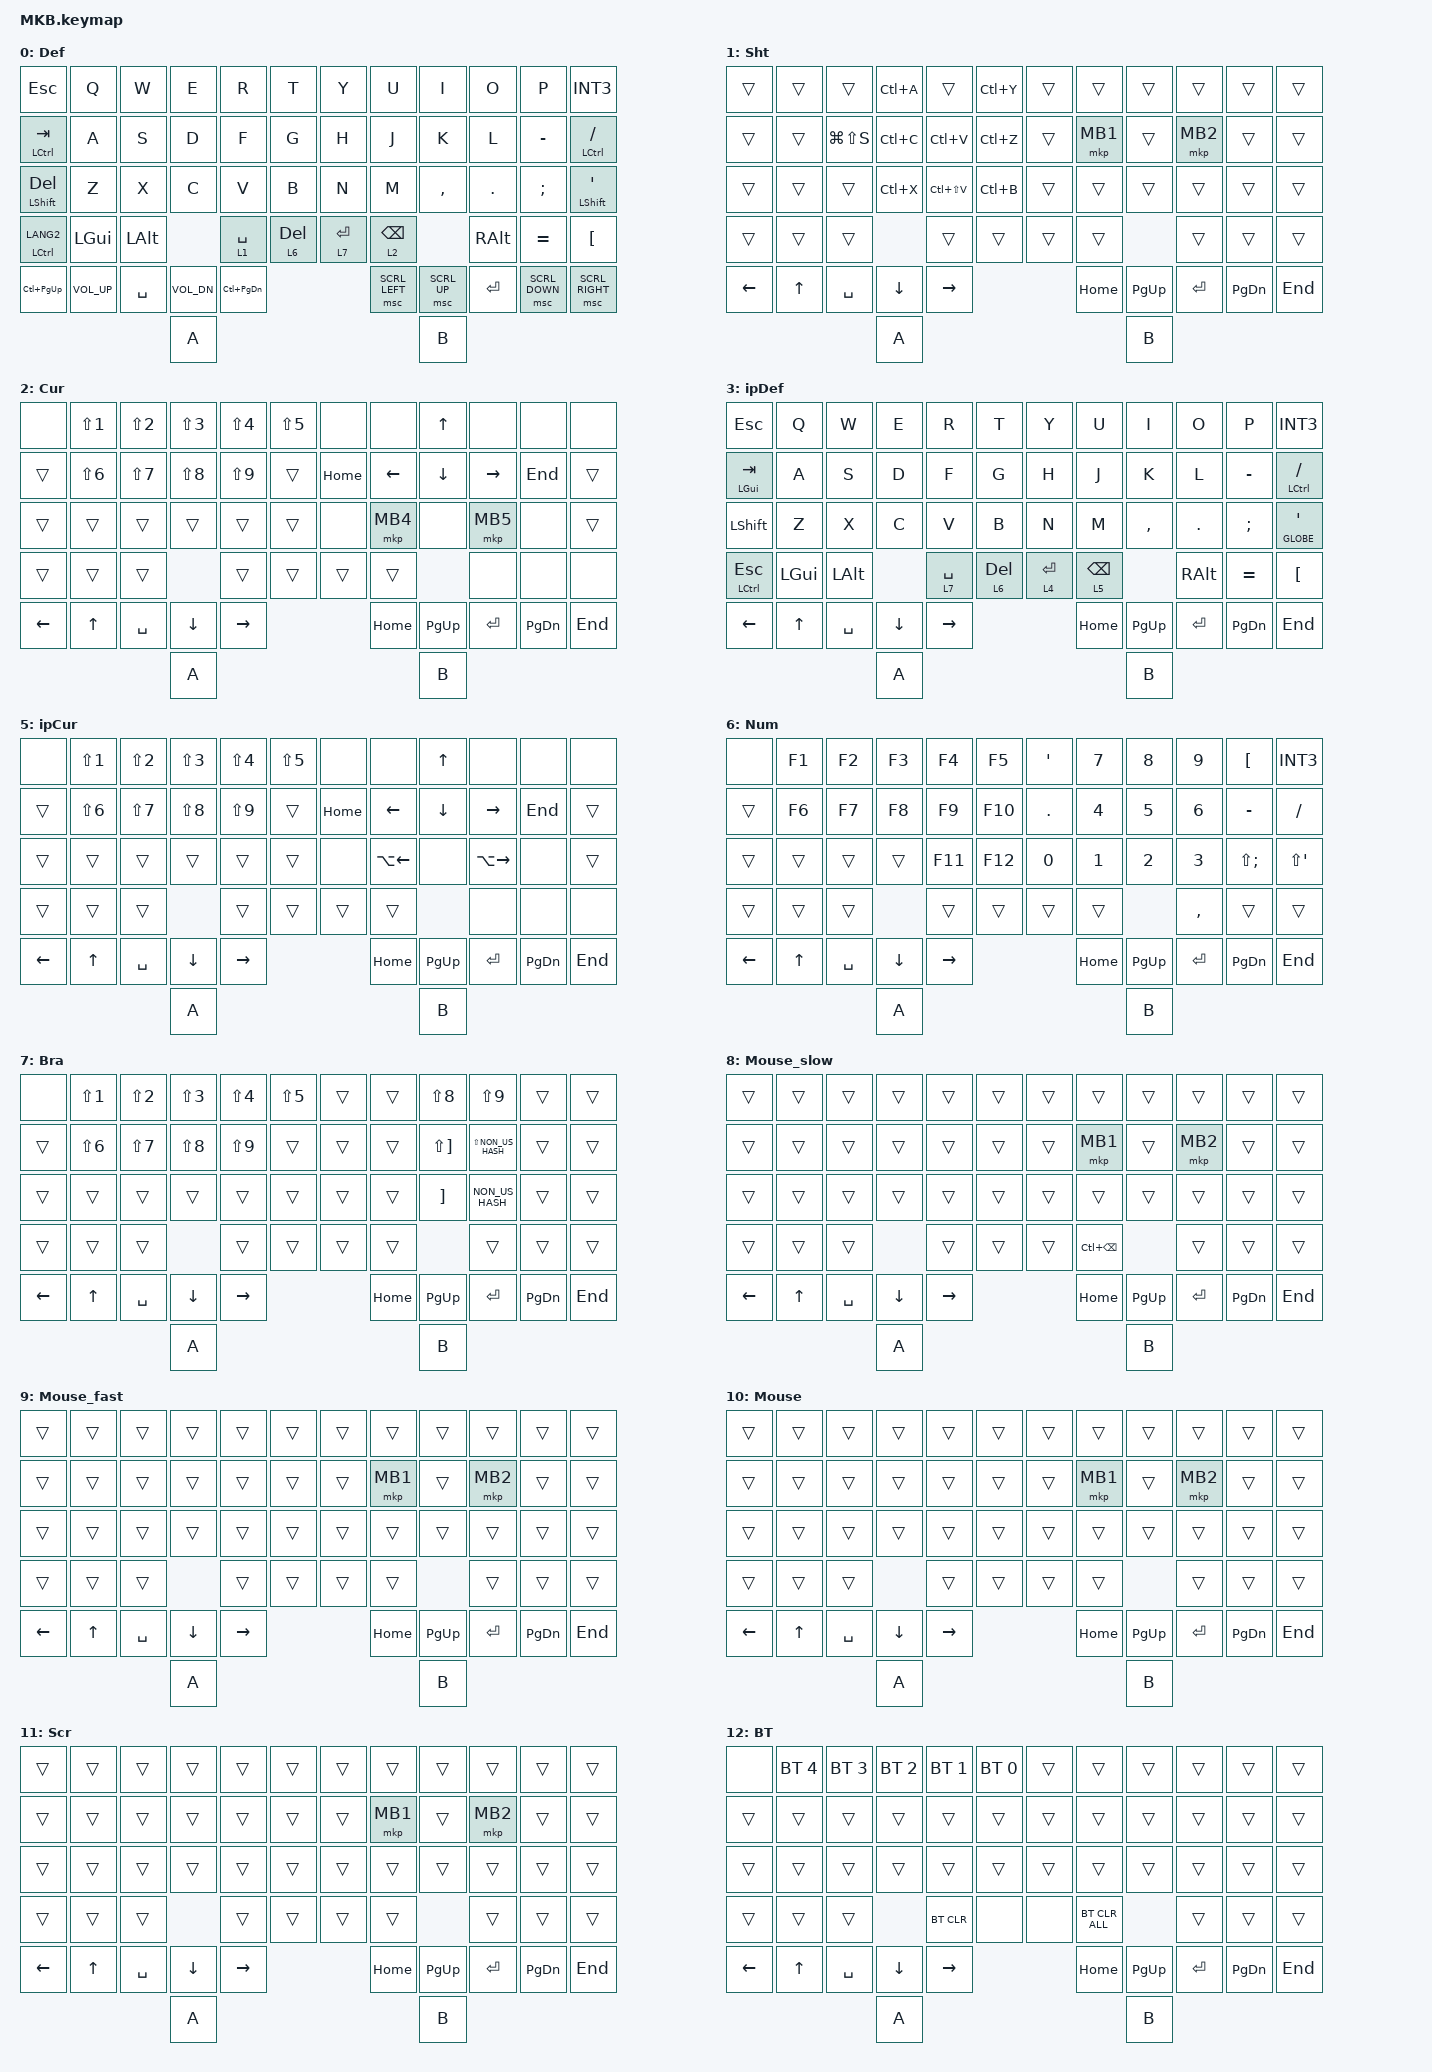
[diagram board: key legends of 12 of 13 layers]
// #include <layout_shift.dtsi>

#include <layout_shift_kp_override.dtsi>
#include <behaviors.dtsi>
#include <dt-bindings/zmk/bt.h>
#include <dt-bindings/zmk/keys.h>
#include <dt-bindings/zmk/pointing.h>

#define DEF 0
#define FUNC 1
#define NUM 2
#define MOUSE 3
#define SCROLL 4
#define BT 5

&mt {
    flavor = "balanced";
    tapping-term-ms = <280>;
    quick-tap-ms = <175>;
    require-prior-idle-ms = <150>;
};

/ {
    combos {
        compatible = "zmk,combos";

        scroll_lang1 {
            bindings = <&lt 11 LANG1>;
            key-positions = <19 20>;
        };

        lang2 {
            bindings = <&kp LANGUAGE_2>;
            key-positions = <15 16>;
        };

        underscore {
            bindings = <&kp LS(INT1)>;
            key-positions = <21 22>;
            layers = <0 6 7 3>;
        };

        shift1 {
            bindings = <&kp LS(N1)>;
            key-positions = <27 28>;
            layers = <0 6 7 3>;
        };

        question {
            bindings = <&kp LS(SLASH)>;
            key-positions = <31 32>;
            layers = <0 6 7 3>;
        };

        bt {
            bindings = <&mo 12>;
            key-positions = <18 23>;
            layers = <0 3>;
        };

        macro_bra_s {
            bindings = <&macro_bra_s>;
            key-positions = <8 9>;
            layers = <0 6 7 3>;
        };

        macro_bra_m {
            bindings = <&macro_bro_m>;
            key-positions = <20 21>;
            layers = <6 7 0 3>;
        };

        macro_bra_l {
            bindings = <&macro_bro_l>;
            key-positions = <32 33>;
            layers = <0 6 7 3>;
        };

        macro_dq {
            bindings = <&macro_dq>;
            key-positions = <2 3>;
            layers = <0 6 7 3>;
        };

        macro_sq {
            bindings = <&macro_sq>;
            key-positions = <14 15>;
            layers = <0 6 7 3>;
        };

        macro_bra_ket {
            bindings = <&macro_bra_ket>;
            key-positions = <26 27>;
            layers = <0 6 7 3>;
        };

        switch_ipad {
            bindings = <&tog 3>;
            key-positions = <12 17>;
            layers = <0 3>;
        };

        delete {
            bindings = <&kp DEL>;
            key-positions = <10 11>;
        };

        mouse3 {
            bindings = <&mkp MB3>;
            key-positions = <19 21>;
        };
    };

    macros {
        macro_bra_s: new_macro {
            compatible = "zmk,behavior-macro";
            #binding-cells = <0>;
            bindings = <&kp LS(N8) &kp LS(N9) &kp LEFT>;
            label = "NEW_MACRO";
        };

        macro_bro_m: macro_bro_m {
            compatible = "zmk,behavior-macro";
            #binding-cells = <0>;
            bindings = <&kp LS(RIGHT_BRACKET) &kp LS(NON_US_HASH) &kp LEFT>;
            label = "MACRO_BRO_M";
        };

        macro_bro_l: macro_bro_L {
            compatible = "zmk,behavior-macro";
            #binding-cells = <0>;
            bindings = <&kp RIGHT_BRACKET &kp NON_US_HASH &kp LEFT>;
            label = "MACRO_BRO_L";
        };

        macro_dq: macro_dq {
            compatible = "zmk,behavior-macro";
            #binding-cells = <0>;
            bindings = <&kp LS(N2) &kp LS(N2) &kp LEFT>;
            label = "MACRO_DQ";
        };

        macro_sq: macro_sq {
            compatible = "zmk,behavior-macro";
            #binding-cells = <0>;
            bindings = <&kp LS(N7) &kp LS(N7) &kp LEFT>;
            label = "MACRO_SQ";
        };

        macro_bra_ket: macro_bra_ket {
            compatible = "zmk,behavior-macro";
            #binding-cells = <0>;
            bindings = <&kp LS(COMMA) &kp LS(DOT) &kp LEFT>;
            label = "MACRO_BRA_KET";
        };
    };

    keymap {
        compatible = "zmk,keymap";

        default_layer {
            label = "Def";
            bindings = <
&kp ESCAPE        &kp Q         &kp W      &kp E         &kp R              &kp T             &kp Y        &kp U            &kp I         &kp O          &kp P           &kp INT3
&mt LCTRL TAB     &kp A         &kp S      &kp D         &kp F              &kp G             &kp H        &kp J            &kp K         &kp L          &kp MINUS       &mt LCTRL SLASH
&mt LSHFT DELETE  &kp Z         &kp X      &kp C         &kp V              &kp B             &kp N        &kp M            &kp COMMA     &kp DOT        &kp SEMICOLON   &mt LSHIFT SINGLE_QUOTE
&mt LCTRL LANG2   &kp LGUI      &kp LALT                 &lt 1 SPACE        &lt 6 DELETE      &lt 7 ENTER  &lt 2 BACKSPACE                &kp RIGHT_ALT  &kp EQUAL       &kp LEFT_BRACKET
&kp LC(PAGE_UP)   &kp C_VOL_UP  &kp SPACE  &kp C_VOL_DN  &kp LC(PAGE_DOWN)                                 &msc SCRL_LEFT   &msc SCRL_UP  &kp ENTER      &msc SCRL_DOWN  &msc SCRL_RIGHT
                                           &kp A                                                                            &kp B
            >;

            sensor-bindings = <&inc_dec_kp C_VOL_UP C_VOL_DN &inc_dec_kp PG_UP PG_DN>;
        };

        shortcut_layer {
            label = "Sht";
            bindings = <
&trans    &trans  &trans         &kp LC(A)  &trans         &kp LC(Y)      &trans  &trans    &trans     &trans     &trans     &trans
&trans    &trans  &kp LG(LS(S))  &kp LC(C)  &kp LC(V)      &kp LC(Z)      &trans  &mkp MB1  &trans     &mkp MB2   &trans     &trans
&trans    &trans  &trans         &kp LC(X)  &kp LC(LS(V))  &kp LC(B)      &trans  &trans    &trans     &trans     &trans     &trans
&trans    &trans  &trans                    &trans         &trans         &trans  &trans               &trans     &trans     &trans
&kp LEFT  &kp UP  &kp SPACE      &kp DOWN   &kp RIGHT                             &kp HOME  &kp PG_UP  &kp ENTER  &kp PG_DN  &kp END
                                 &kp A                                                      &kp B
            >;

            sensor-bindings = <&inc_dec_kp C_VOL_UP C_VOL_DN &inc_dec_kp PG_UP PG_DN>;
        };

        cursor_layer {
            label = "Cur";
            bindings = <
&none     &kp LS(N1)        &kp LS(N2)  &kp LS(N3)  &kp LS(N4)  &kp LS(NUMBER_5)      &none     &none     &kp UP     &none      &none      &none
&trans    &kp LS(NUMBER_6)  &kp LS(N7)  &kp LS(N8)  &kp LS(N9)  &trans                &kp HOME  &kp LEFT  &kp DOWN   &kp RIGHT  &kp END    &trans
&trans    &trans            &trans      &trans      &trans      &trans                &none     &mkp MB4  &none      &mkp MB5   &none      &trans
&trans    &trans            &trans                  &trans      &trans                &trans    &trans               &none      &none      &none
&kp LEFT  &kp UP            &kp SPACE   &kp DOWN    &kp RIGHT                                   &kp HOME  &kp PG_UP  &kp ENTER  &kp PG_DN  &kp END
                                        &kp A                                                             &kp B
            >;

            sensor-bindings =
                <&inc_dec_kp C_VOL_UP C_VOL_DN>,
                <&inc_dec_kp PG_UP PG_DN>;
        };

        ipad_default_layer {
            label = "ipDef";
            bindings = <
&kp ESC           &kp Q         &kp W      &kp E     &kp R        &kp T          &kp Y        &kp U            &kp I      &kp O          &kp P          &kp INT3
&mt LEFT_GUI TAB  &kp A         &kp S      &kp D     &kp F        &kp G          &kp H        &kp J            &kp K      &kp L          &kp MINUS      &mt LCTRL SLASH
&kp LSHFT         &kp Z         &kp X      &kp C     &kp V        &kp B          &kp N        &kp M            &kp COMMA  &kp DOT        &kp SEMICOLON  &mt GLOBE SINGLE_QUOTE
&mt LCTRL ESC     &kp LEFT_GUI  &kp LALT             &lt 7 SPACE  &lt 6 DEL      &lt 4 ENTER  &lt 5 BACKSPACE             &kp RIGHT_ALT  &kp EQUAL      &kp LEFT_BRACKET
&kp LEFT          &kp UP        &kp SPACE  &kp DOWN  &kp RIGHT                                &kp HOME         &kp PG_UP  &kp ENTER      &kp PG_DN      &kp END
                                           &kp A                                                               &kp B
            >;

            sensor-bindings =
                <&inc_dec_kp C_VOL_UP C_VOL_DN>,
                <&inc_dec_kp PG_UP PG_DN>;
        };

        ipad_function_layer {
            label = "ipFnc";
            bindings = <
&trans    &trans  &trans     &trans    &trans     &trans             &trans         &kp LG(A)  &trans             &trans          &trans     &trans
&trans    &trans  &trans     &trans    &trans     &trans             &kp LG(Z)      &kp LG(C)  &kp LG(V)          &kp LS(LG(N3))  &trans     &trans
&trans    &trans  &trans     &trans    &trans     &trans             &kp LG(LS(Z))  &kp LG(X)  &kp LS(LA(LG(V)))  &trans          &trans     &trans
&trans    &trans  &trans               &kp LG(Z)  &kp LS(LG(Z))      &trans         &trans                        &trans          &trans     &trans
&kp LEFT  &kp UP  &kp SPACE  &kp DOWN  &kp RIGHT                                    &kp HOME   &kp PG_UP          &kp ENTER       &kp PG_DN  &kp END
                             &kp A                                                             &kp B
            >;

            sensor-bindings =
                <&inc_dec_kp C_VOL_UP C_VOL_DN>,
                <&inc_dec_kp PG_UP PG_DN>;
        };

        ipad_cursor_layer {
            label = "ipCur";
            bindings = <
&none     &kp LS(N1)        &kp LS(N2)  &kp LS(N3)  &kp LS(N4)  &kp LS(NUMBER_5)      &none     &none         &kp UP     &none          &none      &none
&trans    &kp LS(NUMBER_6)  &kp LS(N7)  &kp LS(N8)  &kp LS(N9)  &trans                &kp HOME  &kp LEFT      &kp DOWN   &kp RIGHT      &kp END    &trans
&trans    &trans            &trans      &trans      &trans      &trans                &none     &kp LA(LEFT)  &none      &kp LA(RIGHT)  &none      &trans
&trans    &trans            &trans                  &trans      &trans                &trans    &trans                   &none          &none      &none
&kp LEFT  &kp UP            &kp SPACE   &kp DOWN    &kp RIGHT                                   &kp HOME      &kp PG_UP  &kp ENTER      &kp PG_DN  &kp END
                                        &kp A                                                                 &kp B
            >;

            sensor-bindings =
                <&inc_dec_kp C_VOL_UP C_VOL_DN>,
                <&inc_dec_kp PG_UP PG_DN>;
        };

        num_layer {
            label = "Num";
            bindings = <
&none     &kp F1  &kp F2     &kp F3    &kp F4     &kp F5       &kp SINGLE_QUOTE  &kp N7    &kp N8     &kp N9     &kp LEFT_BRACKET   &kp INT3
&trans    &kp F6  &kp F7     &kp F8    &kp F9     &kp F10      &kp PERIOD        &kp N4    &kp N5     &kp N6     &kp MINUS          &kp SLASH
&trans    &trans  &trans     &trans    &kp F11    &kp F12      &kp N0            &kp N1    &kp N2     &kp N3     &kp LS(SEMICOLON)  &kp LS(SINGLE_QUOTE)
&trans    &trans  &trans               &trans     &trans       &trans            &trans               &kp COMMA  &trans             &trans
&kp LEFT  &kp UP  &kp SPACE  &kp DOWN  &kp RIGHT                                 &kp HOME  &kp PG_UP  &kp ENTER  &kp PG_DN          &kp END
                             &kp A                                                         &kp B
            >;

            sensor-bindings = <&inc_dec_kp C_VOL_UP C_VOL_DN &inc_dec_kp PG_UP PG_DN>;
        };

        bracket_layer {
            label = "Bra";
            bindings = <
&none     &kp LS(N1)  &kp LS(N2)  &kp LS(N3)  &kp LS(N4)  &kp LS(N5)      &trans  &trans    &kp LS(N8)             &kp LS(N9)           &trans     &trans
&trans    &kp LS(N6)  &kp LS(N7)  &kp LS(N8)  &kp LS(N9)  &trans          &trans  &trans    &kp LS(RIGHT_BRACKET)  &kp LS(NON_US_HASH)  &trans     &trans
&trans    &trans      &trans      &trans      &trans      &trans          &trans  &trans    &kp RIGHT_BRACKET      &kp NON_US_HASH      &trans     &trans
&trans    &trans      &trans                  &trans      &trans          &trans  &trans                           &trans               &trans     &trans
&kp LEFT  &kp UP      &kp SPACE   &kp DOWN    &kp RIGHT                           &kp HOME  &kp PG_UP              &kp ENTER            &kp PG_DN  &kp END
                                  &kp A                                                     &kp B
            >;

            sensor-bindings =
                <&inc_dec_kp C_VOL_UP C_VOL_DN>,
                <&inc_dec_kp PG_UP PG_DN>;
        };

        mouse_slow_layer {
            label = "Mouse_slow";
            bindings = <
&trans    &trans  &trans     &trans    &trans     &trans      &trans  &trans             &trans     &trans     &trans     &trans
&trans    &trans  &trans     &trans    &trans     &trans      &trans  &mkp MB1           &trans     &mkp MB2   &trans     &trans
&trans    &trans  &trans     &trans    &trans     &trans      &trans  &trans             &trans     &trans     &trans     &trans
&trans    &trans  &trans               &trans     &trans      &trans  &kp LC(BACKSPACE)             &trans     &trans     &trans
&kp LEFT  &kp UP  &kp SPACE  &kp DOWN  &kp RIGHT                      &kp HOME           &kp PG_UP  &kp ENTER  &kp PG_DN  &kp END
                             &kp A                                                       &kp B
            >;

            sensor-bindings =
                <&inc_dec_kp C_VOL_UP C_VOL_DN>,
                <&inc_dec_kp PG_UP PG_DN>;
        };

        mouse_fast_layer {
            label = "Mouse_fast";
            bindings = <
&trans    &trans  &trans     &trans    &trans     &trans      &trans  &trans    &trans     &trans     &trans     &trans
&trans    &trans  &trans     &trans    &trans     &trans      &trans  &mkp MB1  &trans     &mkp MB2   &trans     &trans
&trans    &trans  &trans     &trans    &trans     &trans      &trans  &trans    &trans     &trans     &trans     &trans
&trans    &trans  &trans               &trans     &trans      &trans  &trans               &trans     &trans     &trans
&kp LEFT  &kp UP  &kp SPACE  &kp DOWN  &kp RIGHT                      &kp HOME  &kp PG_UP  &kp ENTER  &kp PG_DN  &kp END
                             &kp A                                              &kp B
            >;

            sensor-bindings =
                <&inc_dec_kp C_VOL_UP C_VOL_DN>,
                <&inc_dec_kp PG_UP PG_DN>;
        };

        mouse_layer {
            label = "Mouse";
            bindings = <
&trans    &trans  &trans     &trans    &trans     &trans      &trans  &trans    &trans     &trans     &trans     &trans
&trans    &trans  &trans     &trans    &trans     &trans      &trans  &mkp MB1  &trans     &mkp MB2   &trans     &trans
&trans    &trans  &trans     &trans    &trans     &trans      &trans  &trans    &trans     &trans     &trans     &trans
&trans    &trans  &trans               &trans     &trans      &trans  &trans               &trans     &trans     &trans
&kp LEFT  &kp UP  &kp SPACE  &kp DOWN  &kp RIGHT                      &kp HOME  &kp PG_UP  &kp ENTER  &kp PG_DN  &kp END
                             &kp A                                              &kp B
            >;

            sensor-bindings = <&inc_dec_kp C_VOL_UP C_VOL_DN &inc_dec_kp PG_UP PG_DN>;
        };

        scroll_layer {
            label = "Scr";
            bindings = <
&trans    &trans  &trans     &trans    &trans     &trans      &trans  &trans    &trans     &trans     &trans     &trans
&trans    &trans  &trans     &trans    &trans     &trans      &trans  &mkp MB1  &trans     &mkp MB2   &trans     &trans
&trans    &trans  &trans     &trans    &trans     &trans      &trans  &trans    &trans     &trans     &trans     &trans
&trans    &trans  &trans               &trans     &trans      &trans  &trans               &trans     &trans     &trans
&kp LEFT  &kp UP  &kp SPACE  &kp DOWN  &kp RIGHT                      &kp HOME  &kp PG_UP  &kp ENTER  &kp PG_DN  &kp END
                             &kp A                                              &kp B
            >;

            sensor-bindings = <&inc_dec_kp C_VOL_UP C_VOL_DN &inc_dec_kp PG_UP PG_DN>;
        };

        bt_layer {
            label = "BT";
            bindings = <
&none     &bt BT_SEL 4  &bt BT_SEL 3  &bt BT_SEL 2  &bt BT_SEL 1  &bt BT_SEL 0      &trans  &trans          &trans     &trans     &trans     &trans
&trans    &trans        &trans        &trans        &trans        &trans            &trans  &trans          &trans     &trans     &trans     &trans
&trans    &trans        &trans        &trans        &trans        &trans            &trans  &trans          &trans     &trans     &trans     &trans
&trans    &trans        &trans                      &bt BT_CLR    &none             &none   &bt BT_CLR_ALL             &trans     &trans     &trans
&kp LEFT  &kp UP        &kp SPACE     &kp DOWN      &kp RIGHT                               &kp HOME        &kp PG_UP  &kp ENTER  &kp PG_DN  &kp END
                                      &kp A                                                                 &kp B
            >;

            sensor-bindings = <&inc_dec_kp C_VOL_UP C_VOL_DN &inc_dec_kp PG_UP PG_DN>;
        };
    };
};
